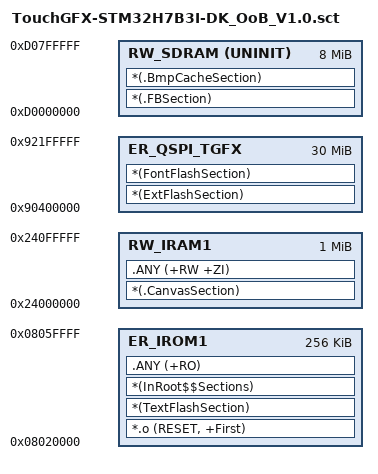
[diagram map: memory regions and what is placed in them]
; *************************************************************
; *** Scatter-Loading Description File generated by uVision ***
; *************************************************************

LR_IROM1 0x08020000 0x00040000  {    ; load region size_region
  ER_IROM1 0x08020000 0x00040000  {  ; load address = execution address
   *.o (RESET, +First)
   *(TextFlashSection)
    *(InRoot$$Sections)
      .ANY (+RO)     
                }
	  
 RW_IRAM1 0x24000000 0x100000  {  ; RW data
  *(.CanvasSection)
   .ANY (+RW +ZI)
   
	}
  }
 	  
	  
LR_QSPI_TGFX 0x90400000 0x1E00000  {    ; load region size_region
    
	ER_QSPI_TGFX 0x90400000  0x1E00000{	
	    *(ExtFlashSection)
		*(FontFlashSection)
				
}
 RW_SDRAM 0xD0000000 UNINIT 0x800000  {  ; RW data
    
   *(.FBSection)
   *(.BmpCacheSection)
   
} 
}
 

 
 
 
 
 
 

